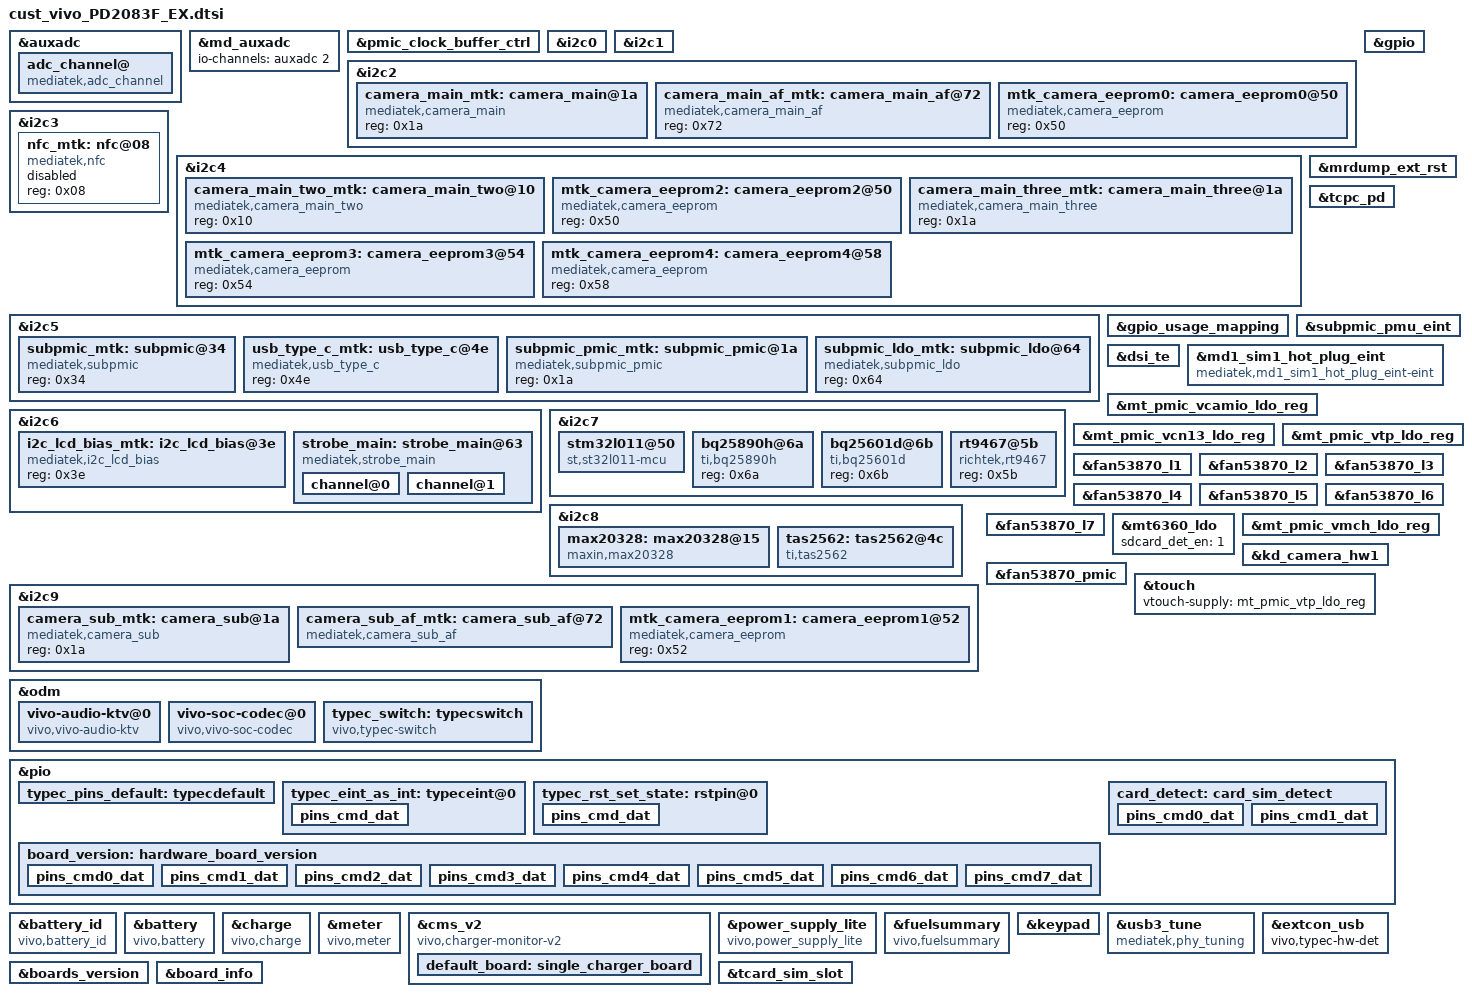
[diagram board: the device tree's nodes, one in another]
/*
 * Generated by MTK SP DrvGen Version: 3.5.160809 for MT6853.
 * 2020-12-24 16:06:12
 * Do Not Modify The File.
 * Copyright Mediatek Inc. (c) 2016.
*/

/*************************
 * ADC DTSI File
*************************/

&auxadc {
	adc_channel@ {
		compatible = "mediatek,adc_channel";
		mediatek,temperature0 = <0>;
		mediatek,temperature1 = <1>;
		mediatek,adc_fdd_rf_params_dynamic_custom_ch = <2>;
		status = "okay";
	};
};
&md_auxadc {
	io-channels = <&auxadc 2>;
};


/*************************
 * CLK_BUF DTSI File
*************************/

&pmic_clock_buffer_ctrl {
	mediatek,clkbuf-quantity = <7>;
	mediatek,clkbuf-config = <2 1 2 2 0 0 1>;
	mediatek,clkbuf-output-impedance = <6 4 4 4 0 0 4>;
	mediatek,clkbuf-controls-for-desense = <0 4 0 4 0 0 0>;
	status = "okay";
};


/*************************
 * I2C DTSI File
*************************/

&i2c0 {
	#address-cells = <1>;
	#size-cells = <0>;
	clock-frequency = <400000>;
	mediatek,use-open-drain;
};

&i2c1 {
	#address-cells = <1>;
	#size-cells = <0>;
	clock-frequency = <400000>;
	mediatek,use-open-drain;
};

&i2c2 {
	#address-cells = <1>;
	#size-cells = <0>;
	clock-frequency = <400000>;
	mediatek,use-open-drain;


	camera_main_mtk:camera_main@1a {
		compatible = "mediatek,camera_main";
		reg = <0x1a>;
		status = "okay";
	};

	camera_main_af_mtk:camera_main_af@72 {
		compatible = "mediatek,camera_main_af";
		reg = <0x72>;
		status = "okay";
	};

	mtk_camera_eeprom0:camera_eeprom0@50 {
		compatible = "mediatek,camera_eeprom";
		reg = <0x50>;
		status = "okay";
	};

};

&i2c3 {
	#address-cells = <1>;
	#size-cells = <0>;
	clock-frequency = <400000>;
	mediatek,use-open-drain;
	nfc_mtk:nfc@08 {
		compatible = "mediatek,nfc";
		reg = <0x08>;
		status = "disabled";
	};

	#include "fan53870.dtsi"
/*
	#include "pm8008.dtsi"	
*/
};

&i2c4 {
	#address-cells = <1>;
	#size-cells = <0>;
	clock-frequency = <400000>;
	mediatek,use-open-drain;


	camera_main_two_mtk:camera_main_two@10 {
		compatible = "mediatek,camera_main_two";
		reg = <0x10>;
		status = "okay";
	};


	mtk_camera_eeprom2:camera_eeprom2@50 {
		compatible = "mediatek,camera_eeprom";
		reg = <0x50>;
		status = "okay";
	};


	camera_main_three_mtk:camera_main_three@1a {
		compatible = "mediatek,camera_main_three";
		reg = <0x1a>;
		status = "okay";
	};


	mtk_camera_eeprom3:camera_eeprom3@54 {
		compatible = "mediatek,camera_eeprom";
		reg = <0x54>;
		status = "okay";
	};

	mtk_camera_eeprom4:camera_eeprom4@58 {
		compatible = "mediatek,camera_eeprom";
		reg = <0x58>;
		status = "okay";
	};

};

&i2c5 {
	#address-cells = <1>;
	#size-cells = <0>;
	clock-frequency = <3400000>;
	mediatek,use-push-pull;
	subpmic_mtk:subpmic@34 {
		compatible = "mediatek,subpmic";
		reg = <0x34>;
		status = "okay";
	};

	usb_type_c_mtk:usb_type_c@4e {
		compatible = "mediatek,usb_type_c";
		reg = <0x4e>;
		status = "okay";
	};

	subpmic_pmic_mtk:subpmic_pmic@1a {
		compatible = "mediatek,subpmic_pmic";
		reg = <0x1a>;
		status = "okay";
	};

	subpmic_ldo_mtk:subpmic_ldo@64 {
		compatible = "mediatek,subpmic_ldo";
		reg = <0x64>;
		status = "okay";
	};

};

&i2c6 {
	#address-cells = <1>;
	#size-cells = <0>;
	clock-frequency = <400000>;
	mediatek,use-open-drain;
	i2c_lcd_bias_mtk:i2c_lcd_bias@3e {
		compatible = "mediatek,i2c_lcd_bias";
		reg = <0x3e>;
		status = "okay";
	};

	strobe_main: strobe_main@63 {
		compatible = "mediatek,strobe_main";
		reg = <0x63>;
		status = "okay";
	};

};

&i2c7 {
	#address-cells = <1>;
	#size-cells = <0>;
	clock-frequency = <400000>;
	mediatek,use-open-drain;
	
};

&i2c8 {
	#address-cells = <1>;
	#size-cells = <0>;
	clock-frequency = <400000>;
	mediatek,use-open-drain;



};

&i2c9 {
	#address-cells = <1>;
	#size-cells = <0>;
	clock-frequency = <400000>;
	mediatek,use-open-drain;

	camera_sub_mtk:camera_sub@1a {
		compatible = "mediatek,camera_sub";
		reg = <0x1a>;
		status = "okay";
	};

	camera_sub_af_mtk:camera_sub_af@72 {
		compatible = "mediatek,camera_sub_af";
		reg = <0x72>;
		status = "okay";
	};

	mtk_camera_eeprom1:camera_eeprom1@52 {
		compatible = "mediatek,camera_eeprom";
		reg = <0x52>;
		status = "okay";
	};
};



/*************************
 * GPIO DTSI File
*************************/

&gpio_usage_mapping {
	GPIO_FDD_BAND_SUPPORT_DETECT_1ST_PIN = <&pio 72 0>;
	GPIO_FDD_BAND_SUPPORT_DETECT_2ND_PIN = <&pio 73 0>;
	GPIO_FDD_BAND_SUPPORT_DETECT_3RD_PIN = <&pio 74 0>;
	GPIO_FDD_BAND_SUPPORT_DETECT_4TH_PIN = <&pio 75 0>;
	GPIO_FDD_BAND_SUPPORT_DETECT_5TH_PIN = <&pio 76 0>;
	GPIO_FDD_BAND_SUPPORT_DETECT_6TH_PIN = <&pio 65 0>;
	GPIO_SIM1_HOT_PLUG = <&pio 77 0>;
	GPIO_SIM2_SCLK = <&pio 119 0>;
	GPIO_SIM2_SRST = <&pio 120 0>;
	GPIO_SIM2_SIO = <&pio 121 0>;
	GPIO_SIM1_SIO = <&pio 122 0>;
	GPIO_SIM1_SRST = <&pio 123 0>;
	GPIO_SIM1_SCLK = <&pio 124 0>;
	GPIO_RF_PWREN_RST_PIN = <&pio 171 0>;
};

&gpio{
	gpio_init_default = <0 0 0 0 1 0 1>,
		<1 0 0 0 0 0 1>,
		<2 0 0 0 0 0 1>,
		<3 0 0 0 1 0 1>,
		<4 0 0 0 1 1 1>,
		<5 0 0 0 1 0 1>,
		<6 0 0 0 1 0 1>,
		<7 0 1 0 1 0 1>,
		<8 0 0 0 1 0 0>,
		<9 0 0 0 1 1 1>,
		<10 0 0 0 1 1 1>,
		<11 0 0 0 0 0 1>,
		<12 2 0 0 1 0 1>,
		<13 2 0 0 1 0 1>,
		<14 0 1 0 1 0 1>,
		<15 0 0 0 0 0 1>,
		<16 7 0 0 1 0 1>,
		<17 7 0 0 1 0 1>,
		<18 0 0 0 0 0 1>,
		<19 0 0 0 0 0 1>,
		<20 1 0 0 0 0 0>,
		<21 1 0 0 0 0 0>,
		<22 1 0 0 0 0 0>,
		<23 1 0 0 0 0 0>,
		<24 2 0 0 0 0 1>,
		<25 2 0 0 0 0 1>,
		<26 2 0 0 0 0 1>,
		<27 2 0 0 1 0 1>,
		<28 0 1 0 1 0 1>,
		<29 0 1 0 1 0 1>,
		<30 0 1 0 1 0 1>,
		<31 0 0 0 1 0 1>,
		<32 0 0 0 1 1 1>,
		<33 1 0 0 0 0 1>,
		<34 1 0 0 0 0 1>,
		<35 1 0 0 1 0 1>,
		<36 1 0 0 0 0 1>,
		<37 0 1 0 1 0 1>,/* fac53870 en <14 0 0 0 0 1 0>*/
		<38 0 1 1 1 0 0>,/* fac53870 reset <14 0 0 0 0 1 0>, */
		<39 0 0 0 1 0 1>,
		<40 0 1 0 1 0 1>,
		<41 0 1 0 1 0 1>,
		<42 7 0 0 1 0 1>,
		<43 7 0 0 1 0 1>,
		<44 7 0 0 1 0 1>,
		<45 7 0 0 0 0 1>,
		<46 7 0 0 1 0 1>,
		<47 7 0 0 1 0 1>,
		<48 7 0 0 1 0 1>,
		<49 1 0 0 0 0 1>,
		<50 1 0 0 0 0 1>,
		<51 1 0 0 0 0 1>,
		<52 1 0 0 0 0 1>,
		<53 0 1 0 1 0 1>,
		<54 0 1 0 1 0 1>,
		<55 0 0 0 0 0 0>,
		<56 0 1 0 1 0 1>,
		<57 0 1 0 0 0 0>,
		<58 0 1 0 1 0 1>,
		<59 1 0 0 1 0 1>,
		<60 0 1 0 1 0 1>,
		<61 1 0 0 1 1 1>,
		<62 1 0 0 0 0 1>,
		<63 1 0 0 1 1 1>,
		<64 1 0 0 0 0 1>,
		<65 0 0 0 1 1 0>,
		<67 0 1 0 1 1 0>,
		<72 0 0 0 1 1 0>,
		<73 0 0 0 1 1 0>,
		<74 0 0 0 1 1 0>,
		<75 0 0 0 1 1 0>,
		<76 0 0 0 1 1 0>,
		<77 1 0 0 0 0 1>,
		<78 0 0 0 0 0 1>,
		<79 1 0 0 1 1 1>,
		<80 0 1 0 1 0 1>,
		<81 3 0 0 1 0 1>,
		<82 0 1 0 1 0 1>,
		<83 1 0 0 0 0 1>,
		<84 1 0 0 1 0 1>,
		<85 1 0 0 0 0 1>,
		<86 0 1 0 0 0 0>,
		<87 2 0 0 1 0 1>,
		<88 0 0 0 0 1 0>,/* fac53870 int <14 0 0 0 0 1 0>, */
		<89 0 0 0 1 0 1>,
		<90 0 1 1 0 0 0>,
		<91 0 0 0 1 1 0>,
		<92 0 0 0 1 1 0>,
		<93 0 1 0 1 0 1>,
		<94 0 1 0 1 0 1>,
		<95 1 0 0 1 0 1>,
		<96 1 0 0 1 0 1>,
		<97 2 0 0 1 0 1>,
		<98 2 0 0 1 0 1>,
		<99 2 0 0 1 1 1>,
		<100 2 0 0 1 1 1>,
		<101 1 0 0 0 0 1>,/*back cam Íâ²¿ÉÏÀ­*/
		<102 1 0 0 0 0 1>,/*back cam Íâ²¿ÉÏÀ­*/
		<103 1 0 0 1 1 1>,
		<104 1 0 0 1 1 1>,
		<105 1 0 0 1 1 1>,/*wide macro cam ÄÚ²¿ÉÏÀ­105: 1001001111*/
		<106 1 0 0 1 1 1>,/*wide macro cam ÄÚ²¿ÉÏÀ­106: 1001001111 */
		<107 1 0 0 1 1 1>,
		<108 1 0 0 1 1 1>,
		<109 1 0 0 1 1 1>,
		<110 1 0 0 1 1 1>,
		<111 1 0 0 1 1 1>,
		<112 1 0 0 1 1 1>,
		<113 1 0 0 1 1 1>,
		<114 1 0 0 1 1 1>,
		<115 1 0 0 0 0 1>,
		<116 1 0 0 0 0 1>,
		<117 1 0 0 0 0 1>,
		<118 1 0 0 0 0 1>,
		<119 1 0 0 0 0 1>,
		<120 1 0 0 0 0 1>,
		<121 1 0 0 1 1 1>,
		<122 1 0 0 1 1 1>,
		<123 1 0 0 0 0 1>,
		<124 1 0 0 0 0 1>,
		<125 1 0 0 0 0 1>,
		<126 1 0 0 1 1 1>,
		<127 1 0 0 1 1 1>,
		<128 1 0 0 1 1 1>,
		<129 1 0 0 1 1 1>,
		<130 1 0 0 1 1 1>,
		<131 0 1 0 1 0 1>,
		<132 0 1 0 1 0 1>,
		<133 0 1 0 1 0 1>,
		<134 0 1 0 1 0 1>,
		<135 0 1 0 1 0 1>,
		<136 0 1 1 1 0 1>,
		<137 0 1 0 1 0 1>,
		<138 0 1 0 1 0 1>,
		<139 0 1 0 1 0 1>,
		<140 0 1 0 1 0 1>,
		<141 1 0 0 0 0 1>,/*front cam Íâ²¿ÉÏÀ­*/
		<142 1 0 0 0 0 1>,/*front cam Íâ²¿ÉÏÀ­*/
		<143 1 0 0 0 0 1>,
		<144 1 0 0 0 0 1>,
		<145 1 0 0 0 0 1>,
		<146 1 0 0 0 0 1>,
		<147 1 0 0 0 0 1>,
		<148 1 0 0 0 0 1>,
		<149 1 0 0 1 0 1>,
		<150 1 0 0 1 0 1>,
		<151 1 0 0 1 0 1>,
		<152 1 0 0 0 0 1>,
		<153 1 0 0 0 0 1>,
		<154 1 0 0 0 0 1>,
		<155 1 0 0 0 0 1>,
		<156 1 0 0 0 0 1>,
		<157 1 0 0 0 0 1>,
		<158 1 0 0 0 0 1>,
		<159 1 0 0 1 0 1>,
		<160 1 0 0 1 0 1>,
		<161 1 0 0 1 0 1>,
		<162 1 0 0 0 0 0>,
		<163 1 0 0 1 0 0>,
		<164 1 0 0 1 0 1>,
		<165 1 0 0 1 0 1>,
		<166 1 0 0 0 0 1>,
		<167 1 0 0 0 0 1>,
		<168 1 0 0 0 0 1>,
		<169 1 0 0 0 0 1>,
		<170 1 0 0 0 0 1>,
		<171 0 1 1 1 0 1>,
		<172 1 0 0 0 0 1>,
		<173 1 0 0 0 0 1>,
		<174 1 0 0 0 0 1>,
		<175 1 0 0 0 0 1>,
		<176 0 1 0 0 0 1>,
		<177 1 0 0 0 0 1>,
		<178 1 0 0 0 0 1>,
		<179 1 0 0 0 0 1>,
		<180 1 0 0 0 0 1>,
		<181 0 1 1 1 0 1>,
		<182 0 1 0 1 0 1>,
		<183 1 0 0 0 0 1>,
		<184 0 1 0 1 0 1>,
		<185 1 0 0 0 0 1>,
		<186 0 0 0 0 0 1>,
		<187 1 0 0 0 0 1>,
		<188 1 0 0 0 0 0>,
		<189 1 0 0 1 0 0>,
		<190 1 0 0 0 0 0>,
		<191 1 0 0 1 0 0>,
		<192 0 0 0 1 0 1>,
		<193 0 0 0 1 0 1>,
		<194 0 0 0 1 0 1>,
		<195 0 0 0 1 0 1>,
		<196 0 0 0 1 0 1>,
		<197 0 0 0 1 0 1>,
		<198 0 0 0 1 0 1>,
		<199 0 0 0 1 0 1>,
		<200 0 0 0 1 0 1>,
		<201 0 0 0 1 0 1>,
		<202 0 0 0 1 0 1>,
		<203 0 0 0 1 0 0>,
		<204 0 0 0 1 0 0>,
		<205 0 0 0 1 0 0>,
		<206 0 0 0 1 0 0>,
		<207 0 0 0 1 0 0>,
		<208 0 0 0 1 0 0>,
		<209 0 0 0 1 0 0>,
		<210 0 0 0 1 0 0>,
		<211 0 0 0 1 0 0>;
};


/*************************
 * EINT DTSI File
*************************/

#include <dt-bindings/interrupt-controller/irq.h>
#include <dt-bindings/interrupt-controller/arm-gic.h>

&mrdump_ext_rst {
	interrupt-parent = <&pio>;
	interrupts = <1 IRQ_TYPE_LEVEL_LOW>;
	deb-gpios = <&pio 1 0>;
	debounce = <512000>;
	status = "okay";
};

&tcpc_pd {
	interrupt-parent = <&pio>;
	interrupts = <9 IRQ_TYPE_EDGE_FALLING>;
	status = "okay";
};

&subpmic_pmu_eint {
	interrupt-parent = <&pio>;
	interrupts = <10 IRQ_TYPE_EDGE_FALLING>;
	status = "okay";
};

&dsi_te {
	interrupt-parent = <&pio>;
	interrupts = <84 IRQ_TYPE_EDGE_RISING>;
	status = "okay";
};

/*************************
 * MD1_EINT DTSI File
*************************/

&md1_sim1_hot_plug_eint {
	compatible = "mediatek,md1_sim1_hot_plug_eint-eint";
	interrupts = <0 8>;
	debounce = <0 1000000>;
	dedicated = <0 0>;
	src_pin = <0 1>;
	sockettype = <0 0>;
	status = "okay";
};



/*************************
 * PMIC DTSI File
*************************/

&mt_pmic_vcamio_ldo_reg {
	regulator-name = "vcamio";
	regulator-default-on = <1>; /* 0:skip, 1: off, 2:on */
	status = "okay";
};

&mt_pmic_vcn13_ldo_reg {
	regulator-name = "vcn13";
	regulator-default-on = <1>; /* 0:skip, 1: off, 2:on */
	status = "okay";
};

&mt_pmic_vtp_ldo_reg {
	regulator-name = "vtp";
	regulator-default-on = <1>; /* 0:skip, 1: off, 2:on */
	status = "okay";
};

/* hope add fan53870 pmic start*/
&fan53870_l1 {
	regulator-name = "fan53870_l1";
	regulator-default-on = <1>; /* 0:skip, 1: off, 2:on */
	status = "okay";
};

&fan53870_l2 {
	regulator-name = "fan53870_l2";
	regulator-default-on = <1>; /* 0:skip, 1: off, 2:on */
	status = "okay";
};

&fan53870_l3 {
	regulator-name = "fan53870_l3";
	regulator-default-on = <1>; /* 0:skip, 1: off, 2:on */
	status = "okay";
};

&fan53870_l4 {
	regulator-name = "fan53870_l4";
	regulator-default-on = <1>; /* 0:skip, 1: off, 2:on */
	status = "okay";
};

&fan53870_l5 {
	regulator-name = "fan53870_l5";
	regulator-default-on = <1>; /* 0:skip, 1: off, 2:on */
	status = "okay";
};

&fan53870_l6 {
	regulator-name = "fan53870_l6";
	regulator-default-on = <1>; /* 0:skip, 1: off, 2:on */
	status = "okay";
};

&fan53870_l7 {
	regulator-name = "fan53870_l7";
	regulator-default-on = <1>; /* 0:skip, 1: off, 2:on */
	status = "okay";
};
/* hope add fan53870 pmic end*/

/* hope add for mt6360 LDO5 use for af power, remove sdcard use LDO5 PMIC start */
&mt6360_ldo {
	sdcard_det_en = <1>;
};
&mt_pmic_vmch_ldo_reg {
	regulator-name = "VMCH";
	regulator-default-on = <1>; /* 0:skip, 1: off, 2:on */
	status = "okay";
};
/* hope add for mt6360 LDO5 use for af power, remove sdcard use LDO5 PMIC end */
&kd_camera_hw1 {
 	cam0_vcamio-supply = <&mt_pmic_vcamio_ldo_reg>;
	cam0_vcamd-supply = <&fan53870_l2>;
	cam0_vcama-supply = <&fan53870_l3>;
	cam0_vmois-supply = <&fan53870_l6>;
	
	cam1_vcamio-supply = <&mt_pmic_vcamio_ldo_reg>;
	cam1_vcamd-supply = <&fan53870_l1>;
	cam1_vcama-supply = <&fan53870_l5>;
//	cam1_vmois-supply = <&fan53870_l7>;
	
	cam2_vcamio-supply = <&mt_pmic_vcamio_ldo_reg>;
	cam2_vcamd-supply = <&mt_pmic_vcn13_ldo_reg>;
	cam2_vcama-supply = <&fan53870_l4>;

	cam4_vcamio-supply = <&mt_pmic_vcamio_ldo_reg>;
	cam4_vcama-supply = <&fan53870_l4>;
	cam0_enable_sensor = "s5kgw3sp13pd2083_mipi_raw";
	cam1_enable_sensor = "s5kgh1sm24pd2083_mipi_raw";
        cam2_enable_sensor = "ov8856pd2083_mipi_raw";
        cam4_enable_sensor = "ov02b10pd2083_mipi_raw";
};

&camera_sub_af_mtk {
	vcamaf-supply = <&fan53870_l7>;
	status = "okay";
};

&fan53870_pmic {
	fan53870,irq = <&pio 88 0>;
	fan53870,reset = <&pio 38 0>;
	fan53870,init-settings = <0x13 0x55>,<0x14 0x16>;

	interrupt-parent = <&pio>;
	interrupts = <88 IRQ_TYPE_EDGE_RISING 88 0>;
	deb-gpios = <&pio 88 0>;
	debounce = <256000>;
	status = "okay";
};

&strobe_main {
	decouple = <0>;
	channel@0 {
		type = <1>;
		ct = <0>;
		part = <0>;
	};
	channel@1 {
		type = <1>;
		ct = <1>;
		part = <0>;
	};
};

&touch {
	vtouch-supply = <&mt_pmic_vtp_ldo_reg>;
	status = "okay";
};

/*************************
 * qinbaoqiang add for audio start
**************************/
&odm {
	vivo-audio-ktv@0 {
		compatible = "vivo,vivo-audio-ktv";
		status = "okay";
	};

	vivo-soc-codec@0 {
		compatible = "vivo,vivo-soc-codec";
		status = "okay";
	};

	typec_switch:typecswitch {
		compatible = "vivo,typec-switch";
		interrupt-parent = <&pio>;
		interrupts = <3 IRQ_TYPE_LEVEL_LOW 3 0>;
		deb-gpios = <&pio 3 0>;
		debounce = <256000>;
		pinctrl-names = "default", "typec_eint_as_int";
		pinctrl-0 = <&typec_pins_default>;
		pinctrl-1 = <&typec_eint_as_int>;
		status = "okay";
	};
};

&pio {
	typec_pins_default: typecdefault {
	};
	typec_eint_as_int: typeceint@0 {
		pins_cmd_dat {
			pinmux = <PINMUX_GPIO3__FUNC_GPIO3>;
			slew-rate = <0>;
			bias-disable;
		};
	};
};

/* typeC audio start */
&i2c8{
	max20328:max20328@15 {
		status = "okay";
		#sound-dai-cells = <0>;
		compatible = "maxin,max20328";
		reg = <0x15>;
		max,usbc-ic-mode = <0>; /* max20328: 0; fsa4480: 1 */
		jack-type = <1>;   /*0:3.5mm, 1:Type-c*/
		switch-type = <0>; /*0:max20328, 1:FS4480*/
		//rst-gpio = <&pio 55 0>;
		pinctrl-names = "typec_rst_set_state";
		pinctrl-0 = <&typec_rst_set_state>;
	};
};

&pio {
	typec_rst_set_state:rstpin@0{
			pins_cmd_dat {
				pinmux = <PINMUX_GPIO55__FUNC_GPIO55>;
				slew-rate = <0>;
				bias-disable;
			};
	};
};
/* typeC audio end */

&i2c8{
	tas2562:tas2562@4c {
		compatible = "ti,tas2562";
		reg = <0x4c>;
		ti,left-channel = <0x4c>;
		ti,channels = <1>; /* channel number */
		ti,reset-gpio = <&pio 136 0>;
		ti,irq-gpio = <&pio 32 0>;

/*
		ti,iv-width = <16>; // IV sense by default is set to 16 bit, in case of power Limiter it should be 12
		ti,vbat-mon = <0>; // By default Vbat should be 0, in case os power limiter it should be 1
*/
		vivo,impedance-min = <3145728>; /*speaker min impedance 6.0ohm*/
		vivo,impedance-max = <5242880>; /*speaker max impedance 10.0ohm*/
		vivo,frequency-min = <400>;
		vivo,frequency-max = <920>;
		vivo,Qt-min = <100>;

		/* book, page, reg, mask, val */
		vivo,reg_table = <0x00 0x00 0x3e 0xff 0x10 
			0x00 0x00 0x40 0xff 0x31>;

		status = "okay";
	};
};

/*************************
 * POWER DTSI File
*************************/
/* fuxi add for battery&charge start */
&battery_id {
	status = "okay";
	compatible = "vivo,battery_id";

	vivo,bat-adc-ctrl-gpio = <&pio 139 0>;

	io-channels = <&auxadc 3>;
	io-channel-names = "battery_id_adc";

	vivo,bat-name = "B-P9(1511053)ATL 4.48V 3990", "UNKNOWN", "UNKNOWN","UNKNOWN";
};

&battery {
	status = "okay";
	compatible = "vivo,battery";

	io-channels = <&auxadc 0>,
		<&auxadc 4>;

	io-channel-names = "primary_board_therm",
		"parallel_board_therm";

	vivo,low-volt-threshold = <3400>;
	vivo,soft-rise-percent = <96>;
	vivo,soft-rise-cumulative = <3>;
	vivo,soft-rise-keep-cumulative = <10>;
	vivo,percnet-sync-delta = <4>;
	vivo,percnet-sync-cumulative = <9>;
	vivo,full-sync-cumulative = <3>;
	vivo,soft-term-percent = <99>;
	vivo,soft-term-cumulative = <30>;
};

&charge {
	status = "okay";
	compatible = "vivo,charge";

	vivo,chg-wdt-s = <40>;
	vivo,re-chg-voltage-mv = <100>;
	vivo,prechg-voltage-mv = <3000>;
	vivo,iprechg-current-ma = <300>;
	vivo,iterm-current-ma = <256>;
	vivo,vreg-voltage-mv = <4460>;
	vivo,vindpm-voltage-mv = <4600>;
	vivo,sys-voltage-min-mv= <3300>;
	vivo,boostv-voltage-mv = <5150>;
	vivo,boostv-ilimit-ma = <1300>;
	vivo,ovp-voltage-mv = <15000>;

	vivo,max14743-en-gpio = <&pio 55 0>;
	vivo,battery-id-vreg-mv = <4600 4430 4430 4430 4430 4430>;
	/*
	 * 0  auto detect charging
	 * 1  vivo-normal chargine
	 * 2  vivo-single engine charging
	 * 3  vivo-dual engine charging
	 * 4  vivo-flash charging
	*/
	vivo,charge-scheme = <0>;
	vivo,direct-charger-enable;

	/*
	 * SUPPORTED_ADAPTER_DEFAULT = 0,
	 * SUPPORTED_ADAPTER_VIVO_LV_DCHG_5V_4500MA = 1,
	 * SUPPORTED_ADAPTER_VIVO_HV_DCHG_10V_2250MA = 2,
	 * SUPPORTED_ADAPTER_QC20__9V_2000MA = 3,
	 * SUPPORTED_ADAPTER_VIVO_HV_DCHG_10V_4000MA = 4,
	 * SUPPORTED_ADAPTER_MAX,
	 */
	vivo,supported-adapter = <4>;

	vivo,primary-ichg-max-ma = <2000>;
	vivo,parallel-ichg-max-ma = <1500>;

	vivo,flashchg-spec-ma = <2000 3300 6000>;
	vivo,fastchg-spec-ma = <2000 2100 3800>;
	vivo,normalchg-spec-ma = <2000 1500 2300>;

	/* 0---PMIC; 1---CHGIC */
	vivo,vbus-detect-source = <1>;

	/*ffc*/
	vivo,ffc-enable;
	vivo,ffc-iterm-ma = <(-750)>;
	vivo,ffc-vreg-mv = <4526>;
	vivo,battery-id-ffc-vreg-mv = <4526 4500 4500 4492 4500 4500>;
	vivo,ffc-temperature-range = <150 450>;
	vivo,ffc-full-vbat-table-size = <3>;
	vivo,ffc-full-vbat-table = <4526 4526 4460>;
	vivo,ffc-full-ibat-table-size = <3>;
	vivo,ffc-full-ibat-table = <150 199 (-698)>,
		<200 349 (-957)>,
		<350 449 (-1137)>;
	vivo,battery-id-ffc-full-ibat-table = <(-698) (-785) (-785) (-499) (-785) (-785)>,
		<(-957) (-1099) (-1099) (-658) (-1099) (-1099)>,
		<(-1137) (-1178) (-1178) (-758) (-1178) (-1178)>;
};

&meter {
	status = "okay";
	compatible = "vivo,meter";

	vivo,load-capacity-delta-max = <60>;
	vivo,poweron-delta-capacity = <20>;
	vivo,poweron-low-capacity = <3>;
	vivo,volt-car-delta = <8>;
	vivo,car-volt-delta = <6>;
	vivo,meter-res-compesate = <10>;
	vivo,ocv-board-compesate = <0>;

	/* 0---AGING_UNSUPPORTED; 1---DRIVER_SUPPORTED; 2---USPACE_SUPPORTED */
	vivo,battery-aging-support = <2>;

	vivo,capacity-mAh = <3990>;
	/*COLD_CHG COLD_DISCHG NORMAL_CHG NORMAL_DISCHG*/
	vivo,car-tune-value = <1045 1000 1045 1000>,
		<1045 1000 1045 1000>,
		<1045 1000 1045 1000>,
		<1045 1000 1045 1000>,
		<1045 1000 1045 1000>,
		<1045 1000 1045 1000>;

	vivo,bats-qmax = <3258 3420 3580 3885 3900>,
		<4250 4340 4741 4980 4920>,
		<3700 4370 4660 4720 4799>,
		<4600 4686 4832 4944 4900>,
		<3276 3346 3458 3524 3514>,
		<3600 3677 3800 3873 3862>;

	/* car-tune adjust remap */
	vivo,car-tune-adjust-enable;
	vivo,car-tune-adjust-size = <3>;
	vivo,car-tune-adjust-table = <0 10 (360) 6>,
		<11 20 (-35) 7>,
		<21 100 (-45) 8>;

	#include "bat_setting/PD2083_battery_table.dtsi"
};

&cms_v2 {
	compatible = "vivo,charger-monitor-v2";
	status = "okay";

	default_board: single_charger_board {
		/*default board: keep in xxxxxx*/
		support-board-version = "xxxxxx";

		vivo,bat-det-method = <0>;//r:0, rc:1, eprom:2, ex-fg:3
		vivo,bat-id-gpio = <&pio 139 0>;

		//vivo,no-bat-warning;
		//vivo,no-chg-timeout;
		vivo,chg-timeout-mins = <900>;

		//high temperature charger current control enable
		vivo,htccc-enable;
		vivo,htccc-data = <46 55 4100000 100000>;

		//vivo,fbon-scale-enable;/*disable default*/
		vivo,fbon-scale-data = <2 100 100>;

		//vivo,switch-scale-enable;/*disable from rom4.0*/
		vivo,switch-scale-data = <75 53>;

		vivo,calling-scale-enable;
		vivo,calling-scale-data = <100 21>;/*ibat:3900 * 0.54 = 2106,more than 1500,not exit dchg*/
		vivo,calling-dchg-disable;

		vivo,weixin-calling-scale-enable;
		vivo,weixin-calling-scale-data = <100 112>;/*5000mA*/

		//vivo,fixed-scale-enable;
		vivo,fixed-scale-data = <120 3800 0>;/*dchg fixed time adjust the max ibat,disable default*/

		/*data processing : batt-temp*/
		vivo,dp-batt-temp-enable;
		vivo,dp-batt-temp-data = <100>;

		/* charging current for devices in exhibition mode */
		vivo,exhibition-mode-current-primary = <2048>;
		vivo,exhibition-mode-current-parallel = <0>;

		//single charger ibat scale base on temperature battery cell info:1C/1.2C 3960mah
		/* tmin, tmax, data, volt1, data_ex1, volt2, data_ex2. */
		vivo,normal-tc-row-col = <10 7>;
		vivo,normal-tc-data = <550 8888 0 0 0 0 0>,
		   <450 549 50 0 0 0 0>,
		   <200 449 100 4200000 70 0 0>,
		   <150 199 70 0 0 0 0>,
		   <100 149 70 4200000 50 0 0>,
		   <50 99 30 0 0 0 0>,
		   <0 49 30 0 0 0 0>,
		   <(-8888) (-1) 0 0 0 0 0>,
		   <(-8888) (-1) 0 0 0 0 0>,
		   <(-8888) (-1) 0 0 0 0 0>;

		/*flash tc parameter*/
	   vivo,flash-normal-tc-row-col = <9 7>;
	   vivo,flash-normal-tc-data = <550 8888 0 0 0 0 0>,
		   <450 549 50 0 0 0 0>,
		   <350 449 151 4300000 120 4460000 90>,
		   <200 349 151 4300000 120 4460000 90>,
		   <150 199 151 4200000 120 4460000 80>,
		   <100 149 100 0 0 0 0>,
		   <50 99 70 4200000 50 0 0>,
		   <0 49 50 0 0 0 0>,
		   <(-8888) (-1) 0 0 0 0 0>;

		/*adjust fastchg base on board temperature and fb off*/
		vivo,intell-charge-enable;
		vivo,parallel-temp-enable = <1 1>;//<x y> x:fb-on y:fb-off

		/* Flash charge fb-on intell param */
		vivo,primary-fbon-tc-row-col = <7 3>;
		vivo,primary-fbon-tc-data = <461 8888 1500>,
			<441 460 2200>,
		   <431 440 2800>,
		   <411 430 3800>,
		   <401 410 4500>,
		   <381 400 5000>,
		   <(-8888) 380 6000>;
		vivo,parallel-fbon-tc-row-col = <1 3>;
		vivo,parallel-fbon-tc-data = <(-8888) 8888 0>;

		/* Flash charge fb-off intell param */
		vivo,primary-fboff-tc-row-col = <6 3>;
		vivo,primary-fboff-tc-data = <421 8888 1500>,
		   <401 420 2700>,
		   <381 400 3800>,
		   <371 380 4200>,
		   <361 370 4800>,
		   <(-8888) 360 6000>;
		vivo,parallel-fboff-tc-row-col = <1 3>;
		vivo,parallel-fboff-tc-data = <(-8888) 8888 0>;

		/* 9v Fast charge fb-on intell param */
		vivo,9v-primary-fbon-tc-row-col = <6 3>;
		vivo,9v-primary-fbon-tc-data = <481 8888 300>,
			<471 480 500>,
			<451 470 900>,
			<421 450 1100>,
			<391 420 1300>,
			<(-8888) 390 1500>;
		vivo,9v-parallel-fbon-tc-row-col = <4 3>;
		vivo,9v-parallel-fbon-tc-data = <416 8888 600>,
			<406 415 700>,
			<391 405 800>,
			<(-8888) 390 1000>;
		// second parallel parameter, for rt9467
		vivo,9v-2nd-parallel-fbon-tc-row-col = <4 3>;
		vivo,9v-2nd-parallel-fbon-tc-data = <416 8888 600>,
			<406 415 700>,
			<391 405 800>,
			<(-8888) 390 1000>;


		/* 9v Fast charge fb-off intell param */
		vivo,9v-primary-fboff-tc-row-col = <7 3>;
		vivo,9v-primary-fboff-tc-data = <451 8888 512>,
			<431 450 512>,
			<411 430 1200>,
			<401 410 1350>,
			<376 400 1600>,
			<371 375 1800>,
			<(-8888) 370 2000>;
		vivo,9v-parallel-fboff-tc-row-col = <6 3>;
		vivo,9v-parallel-fboff-tc-data = <431 8888 500>,
			<411 430 700>,
			<381 410 850>,
			<371 380 1200>,
			<356 370 1300>,
			<(-8888) 355 1500>;
		// second parallel parameter, for rt9467
		vivo,9v-2nd-parallel-fboff-tc-row-col = <6 3>;
		vivo,9v-2nd-parallel-fboff-tc-data = <431 8888 500>,
			<411 430 700>,
			<381 410 790>,
			<371 380 1200>,
			<356 370 1300>,
			<(-8888) 355 1500>;


		/* 5v Normal charge fb-on intell param */
		vivo,5v-primary-fbon-tc-row-col = <4 3>;
		vivo,5v-primary-fbon-tc-data = <491 8888 500>,
			<461 490 800>,
			<431 460 1500>,
			<(-8888) 430 2048>;
		vivo,5v-parallel-fbon-tc-row-col = <1 3>;
		vivo,5v-parallel-fbon-tc-data = <(-8888) 8888 0>;

		/* 5v Normal charge fb-off intell param */
		vivo,5v-primary-fboff-tc-row-col = <4 3>;
		vivo,5v-primary-fboff-tc-data = <491 8888 500>,
			<461 490 800>,
			<431 460 1500>,
			<(-8888) 430 2048>;
		vivo,5v-parallel-fboff-tc-row-col = <1 3>;
		vivo,5v-parallel-fboff-tc-data = <(-8888) 8888 0>;

		// Direct charging param
		vivo,direct-charger-enable;//porting_check
		vivo,ex-bms-psy-name = "bq_bms";

		// bat_baord, usb_conn, pcb_conn(master_bat_conn), bat_conn
		vivo,dchg-ntc-protect-enable;
		vivo,dchg-ntc-protect-data = <750 800 850 850>;

		vivo,adapter-cooldown-data = <900 850 3400>;
		/*adapter power derate*/
		vivo,adapter-power-derate-enable;

		/* usb connecter protect param
		 * USB_PROTECT_NONE = 0,
		 * USB_CONN_TEMP_HEAT_PROTECT = BIT(0),
		 * USB_ID_PROTECT = BIT(1),
		 */
		vivo,usb-connecter-protect-enable = <1>;
		vivo,usb-id-protect-data= <1100 1547 500>;/* 500K, 2M, fcc */
		vivo,usb-conn-heat-protect-data-row-col = <2 4>;
		vivo,usb-conn-heat-protect-data= <260 8888 670 620>,
			<(-8888) 259 570 520>;

		/*
		 * max vbus of adapter:11v, max ibus of adapter:5A
		 * min voltage of battery for half chg:3500mV,max voltage of battery for half charge:4100mV,
		 * 5V2A charge min current threshold: 1000mA,5V2A charge max current threshold:2100mA,
		 * flash charge min current threshold:5000mA,flash charge max current threshold:11000mA
		 */

		/*default parameter*/
		vivo,charge-param-judge-threshold = <5 2 3500 4300 1000 2100 5000 11000>;

		/* factory mode charging test param */
		vivo,charge-test-param-row-col = <12 3>;
		vivo,charge-test-param-data = <0 0 5500>, /* cable resistance, min value, max value */
		        <0 0 5500>, /* master ibus, min ibus, max ibus */
		        <0 0 5500>, /* slave ibus, min ibus, max ibus */
		        <1 20 40>, /* batt therm ntc, min value, max value */
		        <1 20 45>, /* board therm ntc, min value, max value */
		        <1 20 50>, /* sub charger ntc, min value, max value */
		        <0 20 45>, /* usb con ntc, min value, max value */
		        <0 20 45>, /* usb con 1 ntc, double usb NTC, min value, max value */
		        <0 20 45>, /* bat btb master ntc, min value, max value */
		        <0 20 50>, /* bat btb sub ntc, min value, max value */
		        <0 20 50>, /* bat board ntc, min value, max value */
		        <0 20 50>; /* wireless charge coil ntc, min value, max value */

		/*flash parameter*/
	   vivo,flash-charge-param-judge-threshold = <11 3 3500 4100 1000 2200 4000 6100>;
	   /* factory mode charging test param */
	   vivo,flash-charge-test-param-row-col = <12 3>;
	   vivo,flash-charge-test-param-data = <1 0 5500>, /* cable resistance, min value, max value */
			   <1 0 5500>, /* master ibus, min ibus, max ibus */
			   <0 0 5500>, /* slave ibus, min ibus, max ibus */
			   <1 20 40>, /* batt therm ntc, min value, max value */
			   <1 20 45>, /* board therm ntc, min value, max value */
			   <0 20 50>, /* sub charger ntc, min value, max value */
			   <1 20 45>, /* usb con ntc, min value, max value */
			   <0 20 45>, /* usb con 1 ntc, double usb NTC, min value, max value */
			   <1 20 45>, /* bat btb master ntc, min value, max value */
			   <0 20 50>, /* bat btb sub ntc, min value, max value */
			   <0 20 50>, /* bat board ntc, min value, max value */
			   <0 20 50>; /* wireless charge coil ntc, min value, max value */
	};
};

&power_supply_lite {
	status = "okay";
	compatible = "vivo,power_supply_lite";
};

&fuelsummary {
	status = "okay";
	compatible = "vivo,fuelsummary";

	/************************************************************
	 *
	 *  0   vivo-fastchg
	 *  1   qcom-dualchg
	 *  2   mtk-dualchg
	 *  3   qcom-normchg
	 *  4   mtk-normchg
	 *
	 ***********************************************************/
	chg-scheme = <2>;
	fex-version = <3>;
	fbon-ibat = <(-2400)>;
	fboff-ibat = <(-2600)>;
	
	/* 0---AGING_UNSUPPORTED; 1---DRIVER_SUPPORTED; 2---USPACE_SUPPORTED */
	vivo,battery-aging-support = <2>;
};

&i2c7 {
	#address-cells = <1>;
	#size-cells = <0>;
	status = "okay";
	clock-frequency = <100000>;
	stm32l011@50 {
		compatible = "st,st32l011-mcu";
		reg = <0x50>;

		vivo,power-gpio = <&pio 181 0>;//ZC_LDO_EN
		vivo,int-gpio = <&pio 14 0>;//MCU_INT_AP
		vivo,usbsel-gpio = <&pio 184 0>;//USB_SW_EN
		vivo,shift-en-gpio = <&pio 182 0>;//SHIFT_EN
		//vivo,chg-version-gpio = <&pio 64 0>;//°æ±¾Ê¶±ð
		//vivo,sbu-pwr-gpio = <&pio 20 0>;
		ti,temp-cold-degc = <2>;
		ti,temp-hot-degc = <43>;
		vivo,total-limit-max-ma = <6000>;
		vivo,bigdata-collect-time-limit = <95>;//seconds
		vivo,direct-charger-enable;//porting_check

		/*FFC charge: */
		vivo,ffc-support;
		vivo,ffc-temperature-range = <150 450>;
		//vivo,ffc-param-tuning-enable = <1963>;
		vivo,ffc-cc-to-cv-ibat-thr-rc = <1 3>;
		/*<Tmin Tmax current>*/
		vivo,ffc-cc-to-cv-ibat-thr-table = <150 450 4900>;
		vivo,ffc-dchg-cv-mv-rc = <3 2>;
		/*btb_cv,fg_cv*/
		vivo,ffc-dchg-cv-mv-table = <4450 4430>,/*default*/
			<4536 4536>,/*single_charging*/
			<4536 4536>;/*dual_charging*/
		vivo,battery-id-ffc-dchg-btb_cv-mv-table = <4536 4508 4508 4508 4508 4508>;
		vivo,battery-id-ffc-dchg-fg_cv-mv-table = <4536 4500 4500 4492 4500 4500>;

		vivo,cout-int-gpio = <&pio 8 0>;

		vivo,sbu-cable-id-detect-enable;

		vivo,bat-board-temp-enable = <1>;
		vivo,usb-conn-temp-enable = <1>;
		vivo,bat-conn-temp-enable = <1>;

		vivo,master-bat-conn-temp-enable = <2>;
		vivo,dchg-exit-ntc-threshold = <700 650 700 700 1200>;

		/* BQ25970_SINGLE_DCHG:
		 * DCHG_SINGLE_TYPE_22P5W = 0,
		 * DCHG_SINGLE_TYPE_33W = 1,
		 * DCHG_SINGLE_TYPE_44W = 2,
		 * BQ25970_DUAL_DCHG:DCHG_DUAL_TYPE_44W = 3,
		 */
		vivo,dchg-supported-type = <1>;
		/*adapter power derate*/
		vivo,adapter-power-derate-enable;

		//vivo,single-charger-enable;
		vivo,adapter-sha-encryption;

		io-channels = <&auxadc 4>,
			<&auxadc 5>;

		io-channel-names = "sbu2_cable_id_adc",
			"sbu1_cable_id_adc";

		/*cable r limit table :
		  <rmin,rmax, dchg_ibus_max, cable_id_type, limit_count>
		  cable_id_type: 0:effective cable id, 1:other(default) cable id
		 */
		vivo,cable-r-limit-table-rc = <9 5>;
		vivo,cable-r-limit-table = <(-8888) 271 4000 0 0>,
			<272 329 3000 0 0>,
			<330 394 2250 0 0>,
			<395 505 1800 0 0>,
			<506 8888 0 0 0>,
			<(-8888) 329 3000 1 0>,
			<330 394 2250 1 0>,
			<395 505 1800 1 0>,
			<506 8888 0 1 0>;

		/*load firmware profile*/
		vivo,fw-id-range-pct = <100>;
		#include "bat_setting/mcu-firmware-data-33w.dtsi"
		#include "bat_setting/mcu-firmware-data-44w.dtsi"
	};

	bq25890h@6a {
		compatible = "ti,bq25890h";
		reg = <0x6a>;

		//vivo,int-gpio = <&pio 13 0>;
	};

	bq25601d@6b {
		compatible = "ti,bq25601d";
		reg = <0x6b>;

		//vivo,int-gpio = <&pio 5 0>;
		//vivo,enable-gpio = <&pio 187 0>;
	};

	rt9467@5b {
		compatible = "richtek,rt9467";
		reg = <0x5b>;

		//vivo,int-gpio = <&pio 5 0>;
		//vivo,enable-gpio = <&pio 187 0>;
	};

};
/* fuxi add for battery&charge end */


/*************************
 * KPD DTSI File
*************************/

&keypad {
	mediatek,kpd-key-debounce = <1024>;
	mediatek,kpd-sw-pwrkey = <116>;
	mediatek,kpd-hw-pwrkey = <8>;
	mediatek,kpd-sw-rstkey  = <114>;
	mediatek,kpd-hw-rstkey = <17>;
	mediatek,kpd-use-extend-type = <0>;
	/*HW Keycode [0~71] -> Linux Keycode*/
	mediatek,kpd-hw-map-num = <72>;
	mediatek,kpd-hw-init-map = <115 0 0 0 0 0 0 0 0 0 0 0 0 0 0 0 0 0 0 0 0 0 0 0 0 0 0 0 0 0 0 0 0 0 0 0 0 0 0 0 0 0 0 0 0 0 0 0 0 0 0 0 0 0 0 0 0 0 0 0 0 0 0 0 0 0 0 0 0 0 0 0 >;
	mediatek,kpd-pwrkey-eint-gpio = <0>;
	mediatek,kpd-pwkey-gpio-din  = <0>;
	mediatek,kpd-hw-dl-key0 = <17>;
	mediatek,kpd-hw-dl-key1 = <0>;
	mediatek,kpd-hw-dl-key2 = <8>;
	mediatek,kpd-hw-recovery-key = <17>;
	mediatek,kpd-hw-factory-key = <0>;
	status = "okay";
};

/* fengmingli add for usb start */
&usb3_tune {
	compatible = "mediatek,phy_tuning";
	u2_vrt_ref = <0x1>;
	u2_term_ref = <0x1>;
	u2_enhance = <0x3>;
	u2_vrt_ref_host = <0x5>;
	u2_term_ref_host = <0x5>;
	u2_enhance_host = <0x2>;

	board1_version_bit = <5>;
	board1_version_active = <0>;
	u2_vrt_ref1 = <0x5>;
	u2_term_ref1 = <0x5>;
	u2_enhance1 = <0x3>;
	u2_vrt_ref_host1 = <0x5>;
	u2_term_ref_host1 = <0x5>;
	u2_enhance_host1 = <0x2>;
};

&extcon_usb {
	vivo,typec-hw-det;
};
/* fengmingli add for usb end */

&boards_version {
	pinctrl-names = "default";
	pinctrl-0 = <&board_version>;
	gpio_nums = <8>;
	gpios = <65 72 73 74 75 76 91 92>;
	gpios_start = <&pio 65 0>;
};

&board_info {
	vivo,vendor_project_name = "PD2083F_EX";
	vivo,vendor_project_cpu = "MT6853";
	vivo,vendor_project_freq = "2.4";
	vivo,vendor_project_cpunum = <8>;
};

&tcard_sim_slot {
	pinctrl-names = "default";
	pinctrl-0 = <&card_detect>;
        factory-test,sim1-card;
        factory-test,sim2-card;
	//factory-test,tf-card;
	vivo,new_card_detect;
        card-detect-sim1,gpios = <&pio 77 0x0>;
        card-detect-sim2,gpios = <&pio 77 0x0>;
	//card-detect-tf-card,gpios = <&pio 18 0x0>;
};

&pio {
	board_version: hardware_board_version {
		pins_cmd0_dat {
			pinmux = <PINMUX_GPIO65__FUNC_GPIO65>;
			slew-rate = <0>;
			bias-pull-up = <11>;
		};
		pins_cmd1_dat {
			pinmux = <PINMUX_GPIO72__FUNC_GPIO72>;
			slew-rate = <0>;
			bias-pull-up = <11>;
		};
		pins_cmd2_dat {
			pinmux = <PINMUX_GPIO73__FUNC_GPIO73>;
			slew-rate = <0>;
			bias-pull-up = <11>;
		};
		pins_cmd3_dat {
			pinmux = <PINMUX_GPIO74__FUNC_GPIO74>;
			slew-rate = <0>;
			bias-pull-up = <11>;
		};
		pins_cmd4_dat {
			pinmux = <PINMUX_GPIO75__FUNC_GPIO75>;
			slew-rate = <0>;
			bias-pull-up = <11>;
		};
		pins_cmd5_dat {
			pinmux = <PINMUX_GPIO76__FUNC_GPIO76>;
			slew-rate = <0>;
			bias-pull-up = <11>;
		};
		pins_cmd6_dat {
			pinmux = <PINMUX_GPIO91__FUNC_GPIO91>;
			slew-rate = <0>;
			bias-pull-up = <11>;
		};
		pins_cmd7_dat {
			pinmux = <PINMUX_GPIO92__FUNC_GPIO92>;
			slew-rate = <0>;
			bias-pull-up = <11>;
		};
	};

	card_detect: card_sim_detect {
		pins_cmd0_dat {
			pinmux = <PINMUX_GPIO77__FUNC_MD_INT1_C2K_UIM0_HOT_PLUG>;
			slew-rate = <0>;
			bias-disable;
		};
		pins_cmd1_dat {
			pinmux = <PINMUX_GPIO78__FUNC_GPIO78>;
			slew-rate = <0>;
			bias-disable;
		};
		//pins_cmd2_dat {
		//	pinmux = <PINMUX_GPIO18__FUNC_GPIO18>;
		//	slew-rate = <0>;
		//	bias-disable;
		//};
	};
};

